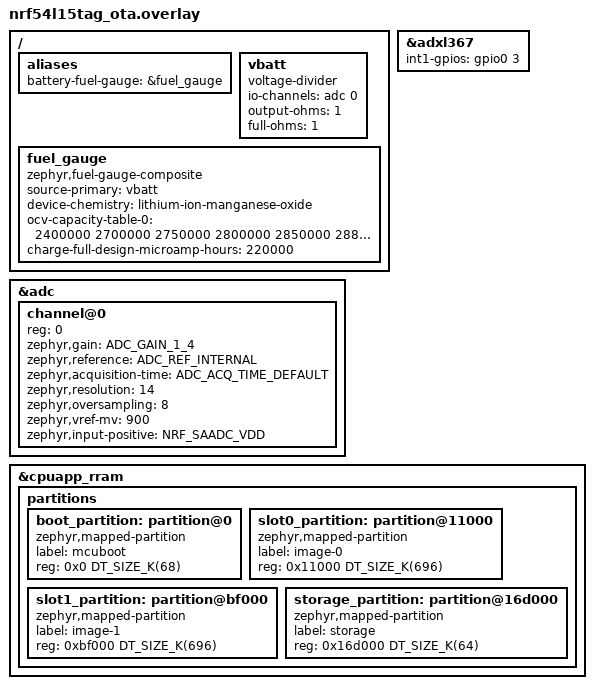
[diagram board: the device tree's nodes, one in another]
/* nRF54L15 Tag layout for MCUboot swap-based OTA. */

/*
 * Nordic PCA20072 revision 1.0.0 schematic sheet 4 connects ADXL367 INT1 to
 * ADXL_IRQ; sheet 2 connects ADXL_IRQ to nRF54L15 P0.03.  The upstream board
 * DTS omits this physical connection, so declare it here for sensor triggers.
 */
&adxl367 {
	int1-gpios = <&gpio0 3 GPIO_ACTIVE_HIGH>;
};

/ {
	aliases {
		battery-fuel-gauge = &fuel_gauge;
	};

	vbatt: vbatt {
		status = "okay";
		compatible = "voltage-divider";
		io-channels = <&adc 0>;
		/* Virtual 1:1 divider: SAADC samples VDD internally. */
		output-ohms = <1>;
		full-ohms = <1>;
	};

	fuel_gauge: fuel_gauge {
		status = "okay";
		compatible = "zephyr,fuel-gauge-composite";
		source-primary = <&vbatt>;
		device-chemistry = "lithium-ion-manganese-oxide";

		/* Nordic's generic CR2032 example; SOC remains an estimate. */
		ocv-capacity-table-0 = <2400000 2700000 2750000 2800000 2850000
					2880000 2900000 2920000 2950000 2980000
					3000000>;
		charge-full-design-microamp-hours = <220000>;
	};
};

&adc {
	#address-cells = <1>;
	#size-cells = <0>;
	status = "okay";

	channel@0 {
		reg = <0>;
		zephyr,gain = "ADC_GAIN_1_4";
		zephyr,reference = "ADC_REF_INTERNAL";
		zephyr,acquisition-time = <ADC_ACQ_TIME_DEFAULT>;
		zephyr,resolution = <14>;
		zephyr,oversampling = <8>;
		zephyr,vref-mv = <900>;
		zephyr,input-positive = <NRF_SAADC_VDD>;
	};
};

/delete-node/ &boot_partition;
/delete-node/ &slot0_partition;
/delete-node/ &slot1_partition;
/delete-node/ &storage_partition;

&cpuapp_rram {
	partitions {
		boot_partition: partition@0 {
			compatible = "zephyr,mapped-partition";
			label = "mcuboot";
			reg = <0x0 DT_SIZE_K(68)>;
		};

		slot0_partition: partition@11000 {
			compatible = "zephyr,mapped-partition";
			label = "image-0";
			reg = <0x11000 DT_SIZE_K(696)>;
		};

		slot1_partition: partition@bf000 {
			compatible = "zephyr,mapped-partition";
			label = "image-1";
			reg = <0xbf000 DT_SIZE_K(696)>;
		};

		storage_partition: partition@16d000 {
			compatible = "zephyr,mapped-partition";
			label = "storage";
			reg = <0x16d000 DT_SIZE_K(64)>;
		};
	};
};
